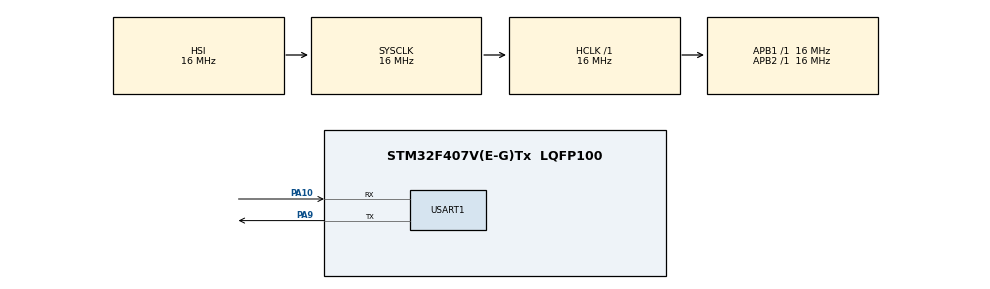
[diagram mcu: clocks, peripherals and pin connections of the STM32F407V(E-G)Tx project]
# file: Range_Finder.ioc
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Mcu.Family=STM32F4
Mcu.Name=STM32F407V(E-G)Tx
Mcu.Package=LQFP100
NVIC.PriorityGroup=NVIC_PRIORITYGROUP_4
NVIC.USART1_IRQn=true\:0\:0\:false\:false\:true\:true\:true\:true
PA10.Mode=Asynchronous
PA10.Signal=USART1_RX
PA9.Mode=Asynchronous
PA9.Signal=USART1_TX
ProjectManager.HeapSize=0x200
ProjectManager.StackSize=0x400
ProjectManager.TargetToolchain=STM32CubeIDE
RCC.AHBFreq_Value=16000000
RCC.APB1Freq_Value=16000000
RCC.APB2Freq_Value=16000000
RCC.CortexFreq_Value=16000000
RCC.HSE_VALUE=25000000
RCC.HSI_VALUE=16000000
RCC.LSE_VALUE=32768
RCC.SYSCLKFreq_VALUE=16000000
RCC.VCOOutputFreq_Value=192000000
USART1.VirtualMode=VM_ASYNC
board=custom

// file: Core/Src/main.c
/* USER CODE BEGIN Header */
/**
  ******************************************************************************
  * @file           : main.c
  * @brief          : Main program body
  ******************************************************************************
  * @attention
  *
  * Copyright (c) 2026 STMicroelectronics.
  * All rights reserved.
  *
  * This software is licensed under terms that can be found in the LICENSE file
  * in the root directory of this software component.
  * If no LICENSE file comes with this software, it is provided AS-IS.
  *
  ******************************************************************************
  */
/* USER CODE END Header */
#include <stdio.h>
#include "main.h"
#include "usart.h"
#include "gpio.h"
#include "stm32f4xx_it.h"
/* USER CODE BEGIN Includes */
#include "circular_buffer.h"
#include "parser.h"
/* USER CODE END Includes */
/*********************************This is needed for using SWV printf**************************/

int _write(int file, char *ptr, int len) {
    for (int i = 0; i < len; i++) {
        ITM_SendChar((*ptr++));
    }
    return len;
}

/* USER CODE BEGIN PV */
Msg_Data_t lidarData;
volatile Msg_Data_t lastFrame;
circBuff circularBuffer;
volatile uint32_t badFrameCount;
volatile uint8_t rxData;
/* USER CODE END PV */

void SystemClock_Config(void);
/* USER CODE BEGIN PFP */
uint32_t findMean(circBuff c);
/* USER CODE END PFP */

int main(void)
{

  /* MCU Configuration--------------------------------------------------------*/

  /* Reset of all peripherals, Initializes the Flash interface and the Systick. */
  HAL_Init();

  /* Configure the system clock */
  SystemClock_Config();

  /* Initialize all configured peripherals */
  MX_GPIO_Init();
  MX_USART1_UART_Init();
  /* USER CODE BEGIN 2 */
  circularBuffer = CircularBuffer_Init();
  printf("Starting program...\n");
  HAL_UART_Receive_IT(&huart1, (uint8_t*)&rxData, 1);
  /* USER CODE END 2 */

  /* Infinite loop */
  while (1)
  {

    /* USER CODE BEGIN 3 */
    if(CircularBuffer_IsHalfFull(circularBuffer))
    {
      uint32_t average = findMean(circularBuffer);
      printf("dist: %u, amp: %u, temp: %u\n", lastFrame.dist, lastFrame.amps, lastFrame.temp);
      printf("distance: %lu \n", average);
    }
  }
  /* USER CODE END 3 */
}

void SystemClock_Config(void)
{
  RCC_OscInitTypeDef RCC_OscInitStruct = {0};
  RCC_ClkInitTypeDef RCC_ClkInitStruct = {0};

  /** Configure the main internal regulator output voltage
  */
  __HAL_RCC_PWR_CLK_ENABLE();
  __HAL_PWR_VOLTAGESCALING_CONFIG(PWR_REGULATOR_VOLTAGE_SCALE1);

  /** Initializes the RCC Oscillators according to the specified parameters
  * in the RCC_OscInitTypeDef structure.
  */
  RCC_OscInitStruct.OscillatorType = RCC_OSCILLATORTYPE_HSI;
  RCC_OscInitStruct.HSIState = RCC_HSI_ON;
  RCC_OscInitStruct.HSICalibrationValue = RCC_HSICALIBRATION_DEFAULT;
  RCC_OscInitStruct.PLL.PLLState = RCC_PLL_NONE;
  if (HAL_RCC_OscConfig(&RCC_OscInitStruct) != HAL_OK)
  {
    Error_Handler();
  }

  /** Initializes the CPU, AHB and APB buses clocks
  */
  RCC_ClkInitStruct.ClockType = RCC_CLOCKTYPE_HCLK|RCC_CLOCKTYPE_SYSCLK
                              |RCC_CLOCKTYPE_PCLK1|RCC_CLOCKTYPE_PCLK2;
  RCC_ClkInitStruct.SYSCLKSource = RCC_SYSCLKSOURCE_HSI;
  RCC_ClkInitStruct.AHBCLKDivider = RCC_SYSCLK_DIV1;
  RCC_ClkInitStruct.APB1CLKDivider = RCC_HCLK_DIV1;
  RCC_ClkInitStruct.APB2CLKDivider = RCC_HCLK_DIV1;

  if (HAL_RCC_ClockConfig(&RCC_ClkInitStruct, FLASH_LATENCY_0) != HAL_OK)
  {
    Error_Handler();
  }
}

/* USER CODE BEGIN 4 */
//Drains buffer then finds average of all distance values
uint32_t findMean(circBuff c)
{
  uint32_t sum = 0, count = 0;
  Item data;
  while(CircularBuffer_Get(c, &data))
  {
    sum += data;
    count++;
  }
  //Avoid dividing by zero
  return count ? sum/count : 0;
}

/* UART receive callback*/
void HAL_UART_RxCpltCallback(UART_HandleTypeDef *huart)
{
  Return_Status_t parserRetVal = Parser_AddByte(&lidarData, rxData);

  //Anything below 100Amps is inaccurate
  if(parserRetVal == PARSER_DATA_FRAME_READY && lidarData.amps > 100)
  {
    lastFrame = lidarData;
    CircularBuffer_Put(circularBuffer, lidarData.dist);
  }
  else if(parserRetVal == PARSER_CHECKSUM_ERROR)
  {
    badFrameCount++;
  }
  //Re enable interrupt
  HAL_UART_Receive_IT(&huart1, (uint8_t*)&rxData, 1);
}

//Handle a UART error by terminating reception
void HAL_UART_ErrorCallback(UART_HandleTypeDef *huart)
{
  HAL_UART_Receive_IT(&huart1, (uint8_t*)&rxData, 1);
}
/* USER CODE END 4 */

void Error_Handler(void)
{
  __disable_irq();
  while (1)
  {
  }
}
#ifdef USE_FULL_ASSERT
/**
  * @brief  Reports the name of the source file and the source line number
  *         where the assert_param error has occurred.
  * @param  file: pointer to the source file name
  * @param  line: assert_param error line source number
  * @retval None
  */
void assert_failed(uint8_t *file, uint32_t line)
{
  /* USER CODE BEGIN 6 */
  /* User can add his own implementation to report the file name and line number,
     ex: printf("Wrong parameters value: file %s on line %d\r\n", file, line) */
  while(1);
  /* USER CODE END 6 */
}
#endif /* USE_FULL_ASSERT */
